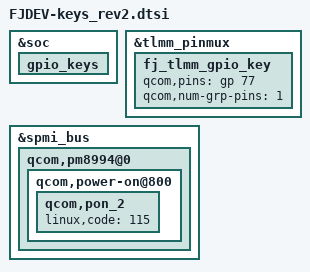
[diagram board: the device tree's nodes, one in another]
/*
 * FJDEV-keys_rev2.dtsi
 *
 * COPYRIGHT(C) FUJITSU CONNECTED TECHNOLOGIES LIMITED 2016
 *
 * This program is free software; you can redistribute it and/or
 * modify it under the terms of the GNU General Public License
 * as published by the Free Software Foundation; version 2
 * of the License.
 *
 * This program is distributed in the hope that it will be useful,
 * but WITHOUT ANY WARRANTY; without even the implied warranty of
 * MERCHANTABILITY or FITNESS FOR A PARTICULAR PURPOSE. See the
 * GNU General Public License for more details.
 *
 * You should have received a copy of the GNU General Public License
 * along with this program; if not, write to the Free Software
 * Foundation, Inc., 59 Temple Place - Suite 330, Boston, MA 02111-1307, USA.
 */

/* FCNT LIMITED:2016-02-23 H16100736 add start */
&soc {
	/delete-node/ up-irq;
	gpio_keys {
		/delete-node/ vol_up;
	};
};

&tlmm_pinmux {
	fj_tlmm_gpio_key {
		qcom,pins = <&gp 77>;
		qcom,num-grp-pins = <1>;
	};
};

&spmi_bus {
	qcom,pm8994@0 {
		qcom,power-on@800 {
			qcom,pon_2 {
				linux,code = <115>;
			};
		};
	};
};
/* FCNT LIMITED:2016-02-23 H16100736 add end */
